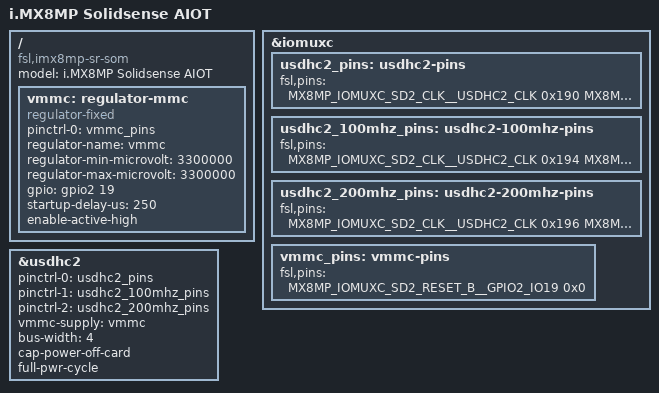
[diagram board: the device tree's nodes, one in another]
/dts-v1/;

#include <dt-bindings/leds/common.h>

#include "imx8mp-sr-som.dtsi"

/ {
	model = "i.MX8MP Solidsense AIOT";
	compatible = "fsl,imx8mp-sr-som", "fsl,imx8mp";

	vmmc: regulator-mmc {
		compatible = "regulator-fixed";
		pinctrl-names = "default";
		pinctrl-0 = <&vmmc_pins>;
		regulator-name = "vmmc";
		regulator-min-microvolt = <3300000>;
		regulator-max-microvolt = <3300000>;
		gpio = <&gpio2 19 GPIO_ACTIVE_HIGH>;
		startup-delay-us = <250>;
		enable-active-high;
	};
};

&iomuxc {
	usdhc2_pins: usdhc2-pins {
		fsl,pins = <
			MX8MP_IOMUXC_SD2_CLK__USDHC2_CLK		0x190
			MX8MP_IOMUXC_SD2_CMD__USDHC2_CMD		0x1d0
			MX8MP_IOMUXC_SD2_DATA0__USDHC2_DATA0		0x1d0
			MX8MP_IOMUXC_SD2_DATA1__USDHC2_DATA1		0x1d0
			MX8MP_IOMUXC_SD2_DATA2__USDHC2_DATA2		0x1d0
			MX8MP_IOMUXC_SD2_DATA3__USDHC2_DATA3		0x1d0
			MX8MP_IOMUXC_GPIO1_IO04__USDHC2_VSELECT		0x140
			MX8MP_IOMUXC_SD2_CD_B__USDHC2_CD_B		0x140
		>;
	};

	usdhc2_100mhz_pins: usdhc2-100mhz-pins {
		fsl,pins = <
			MX8MP_IOMUXC_SD2_CLK__USDHC2_CLK		0x194
			MX8MP_IOMUXC_SD2_CMD__USDHC2_CMD		0x1d4
			MX8MP_IOMUXC_SD2_DATA0__USDHC2_DATA0		0x1d4
			MX8MP_IOMUXC_SD2_DATA1__USDHC2_DATA1		0x1d4
			MX8MP_IOMUXC_SD2_DATA2__USDHC2_DATA2		0x1d4
			MX8MP_IOMUXC_SD2_DATA3__USDHC2_DATA3		0x1d4
			MX8MP_IOMUXC_GPIO1_IO04__USDHC2_VSELECT 	0x140
			MX8MP_IOMUXC_SD2_CD_B__USDHC2_CD_B		0x140
		>;
	};

	usdhc2_200mhz_pins: usdhc2-200mhz-pins {
		fsl,pins = <
			MX8MP_IOMUXC_SD2_CLK__USDHC2_CLK		0x196
			MX8MP_IOMUXC_SD2_CMD__USDHC2_CMD		0x1d6
			MX8MP_IOMUXC_SD2_DATA0__USDHC2_DATA0		0x1d6
			MX8MP_IOMUXC_SD2_DATA1__USDHC2_DATA1		0x1d6
			MX8MP_IOMUXC_SD2_DATA2__USDHC2_DATA2		0x1d6
			MX8MP_IOMUXC_SD2_DATA3__USDHC2_DATA3		0x1d6
			MX8MP_IOMUXC_GPIO1_IO04__USDHC2_VSELECT		0x140
			MX8MP_IOMUXC_SD2_CD_B__USDHC2_CD_B		0x140
		>;
	};

	vmmc_pins: vmmc-pins {
		fsl,pins = <
			MX8MP_IOMUXC_SD2_RESET_B__GPIO2_IO19		0x0
		>;
	};
};

&usdhc2 {
	pinctrl-names = "default", "state_100mhz", "state_200mhz";
	pinctrl-0 = <&usdhc2_pins>;
	pinctrl-1 = <&usdhc2_100mhz_pins>;
	pinctrl-2 = <&usdhc2_200mhz_pins>;
	vmmc-supply = <&vmmc>;
	bus-width = <4>;
	cap-power-off-card;
	full-pwr-cycle;
	status = "okay";
};
